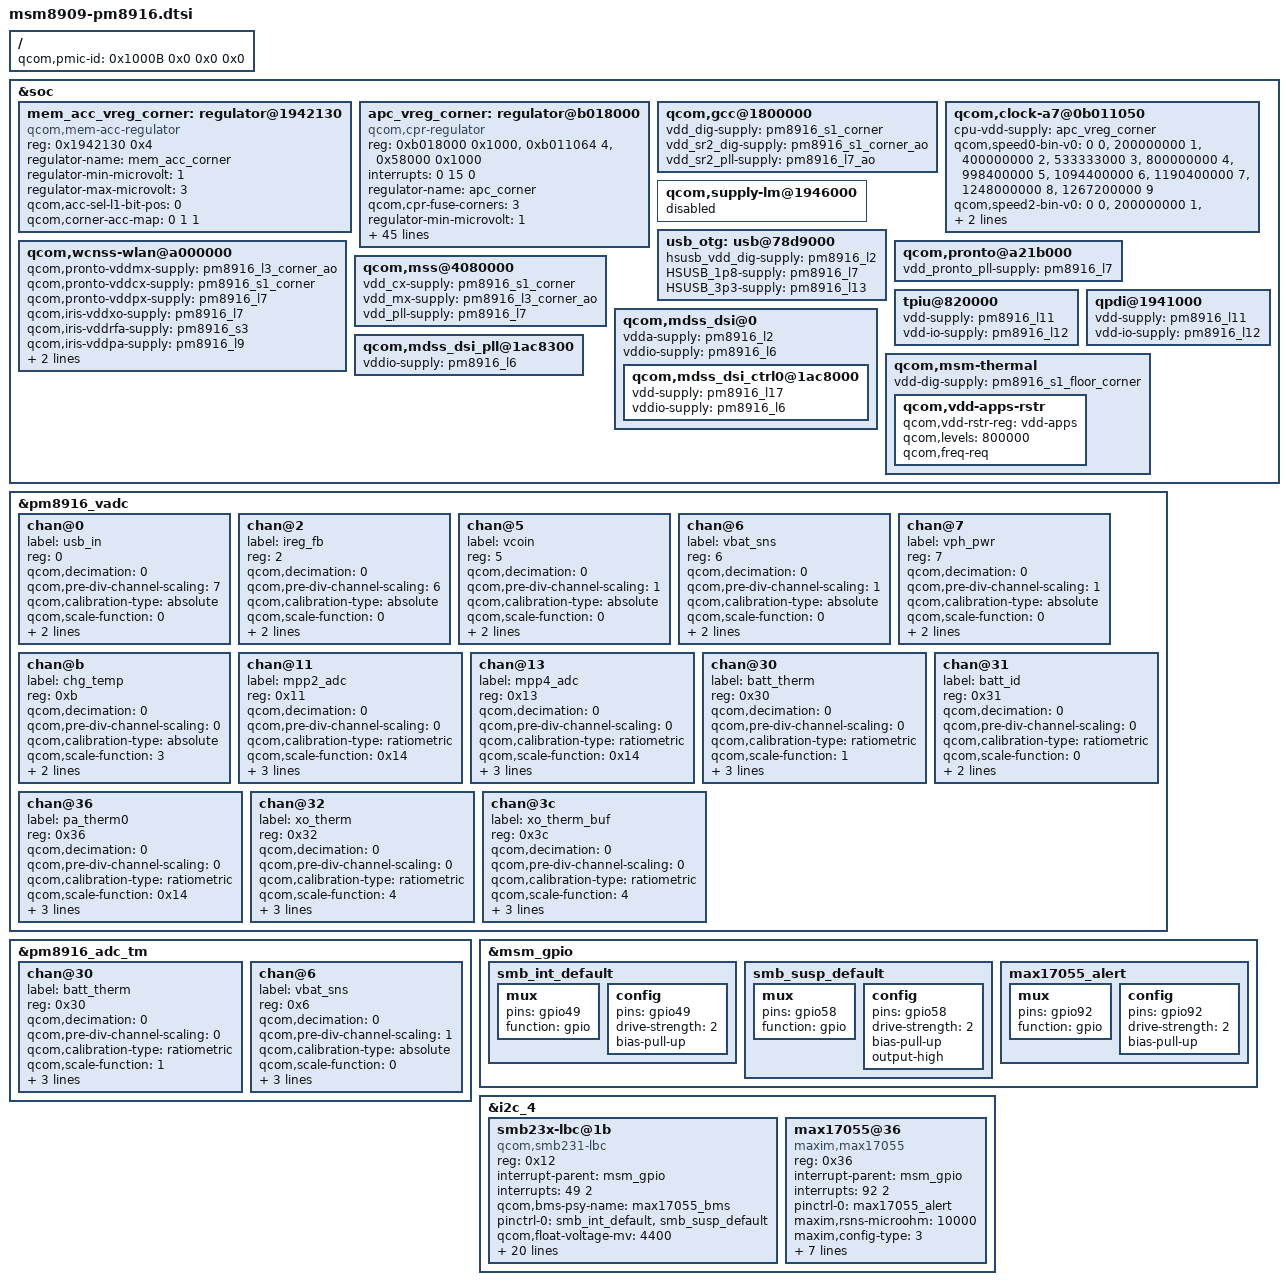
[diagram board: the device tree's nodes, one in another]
/*
 * Copyright (c) 2014-2016, The Linux Foundation. All rights reserved.
 *
 * This program is free software; you can redistribute it and/or modify
 * it under the terms of the GNU General Public License version 2 and
 * only version 2 as published by the Free Software Foundation.
 *
 * This program is distributed in the hope that it will be useful,
 * but WITHOUT ANY WARRANTY; without even the implied warranty of
 * MERCHANTABILITY or FITNESS FOR A PARTICULAR PURPOSE.  See the
 * GNU General Public License for more details.
 */

#include "msm-pm8916-rpm-regulator.dtsi"
#include "msm-pm8916.dtsi"
#include "msm8916-regulator.dtsi"
#include "msm8909-pm8916-camera.dtsi"

/ {
	qcom,pmic-id = <0x1000B 0x0 0x0 0x0>;
};

&soc {
	/* remove msm8916 acc/cpr regulator node */
	/delete-node/ regulator@1946000;
	/delete-node/ regulator@b018000;

	mem_acc_vreg_corner: regulator@1942130 {
		compatible = "qcom,mem-acc-regulator";
		reg = <0x1942130 0x4>;
		reg-names = "acc-sel-l1";
		regulator-name = "mem_acc_corner";
		regulator-min-microvolt = <1>;
		regulator-max-microvolt = <3>;

		qcom,acc-sel-l1-bit-pos = <0>;
		qcom,corner-acc-map = <0 1 1>;
	};

	apc_vreg_corner: regulator@b018000 {
		compatible = "qcom,cpr-regulator";
		reg = <0xb018000 0x1000>, <0xb011064 4>, <0x58000 0x1000>;
		reg-names = "rbcpr", "rbcpr_clk", "efuse_addr";
		interrupts = <0 15 0>;
		regulator-name = "apc_corner";
		qcom,cpr-fuse-corners = <3>;
		regulator-min-microvolt = <1>;
		regulator-max-microvolt = <9>;

		qcom,cpr-voltage-ceiling = <1050000 1225000 1350000>;
		qcom,cpr-voltage-floor = <1050000 1050000 1155000>;
		vdd-apc-supply = <&pm8916_s2>;

		qcom,vdd-mx-corner-map = <4 5 7>;
		qcom,vdd-mx-vmin-method = <4>;
		vdd-mx-supply = <&pm8916_l3_corner_ao>;
		qcom,vdd-mx-vmax = <7>;

		mem-acc-supply = <&mem_acc_vreg_corner>;

		qcom,cpr-ref-clk = <19200>;
		qcom,cpr-timer-delay = <5000>;
		qcom,cpr-timer-cons-up = <0>;
		qcom,cpr-timer-cons-down = <2>;
		qcom,cpr-irq-line = <0>;
		qcom,cpr-step-quotient = <26>;
		qcom,cpr-up-threshold = <0>;
		qcom,cpr-down-threshold = <2>;
		qcom,cpr-idle-clocks = <15>;
		qcom,cpr-gcnt-time = <1>;
		qcom,vdd-apc-step-up-limit = <1>;
		qcom,vdd-apc-step-down-limit = <1>;
		qcom,cpr-apc-volt-step = <12500>;

		qcom,cpr-fuse-row = <26 0>;
		qcom,cpr-fuse-target-quot = <42 24 6>;
		qcom,cpr-fuse-ro-sel = <61 61 54>;
		qcom,cpr-fuse-bp-cpr-disable = <58>;
		qcom,cpr-fuse-init-voltage =
					<26 36 6 0>,
					<26 18 6 0>,
					<26 0 6 0>;
		qcom,cpr-fuse-revision = <26 59 2 0>;
		qcom,cpr-init-voltage-ref = <1050000 1225000 1350000>;
		qcom,cpr-init-voltage-step = <10000>;
		qcom,cpr-corner-map = <1 1 2 2 3 3 3 3 3>;
		qcom,cpr-init-voltage-as-ceiling;
		qcom,cpr-corner-frequency-map =
					<1 200000000>,
					<2 400000000>,
					<3 533330000>,
					<4 800000000>,
					<5 998400000>,
					<6 1094400000>,
					<7 1190400000>,
					<8 1248000000>,
					<9 1267200000>;
		qcom,speed-bin-fuse-sel = <1 34 3 0>;
		qcom,cpr-speed-bin-max-corners =
					<0 0 2 4 9>,
					<2 0 2 4 6>;
		qcom,cpr-quot-adjust-scaling-factor-max = <1400>;
		qcom,cpr-enable;
	};

	qcom,gcc@1800000 {
		vdd_dig-supply = <&pm8916_s1_corner>;
		vdd_sr2_dig-supply = <&pm8916_s1_corner_ao>;
		vdd_sr2_pll-supply = <&pm8916_l7_ao>;
	};

	qcom,clock-a7@0b011050 {
		cpu-vdd-supply = <&apc_vreg_corner>;
		qcom,speed0-bin-v0 =
			<          0 0>,
			<  200000000 1>,
			<  400000000 2>,
			<  533333000 3>,
			<  800000000 4>,
			<  998400000 5>,
			< 1094400000 6>,
			< 1190400000 7>,
			< 1248000000 8>,
			< 1267200000 9>;

		qcom,speed2-bin-v0 =
			<          0 0>,
			<  200000000 1>,
			<  400000000 2>,
			<  533333000 3>,
			<  800000000 4>,
			<  998400000 5>,
			< 1094400000 6>;
	};

	qcom,supply-lm@1946000 {
		status = "disabled";
	};

	qcom,wcnss-wlan@a000000 {
		qcom,pronto-vddmx-supply = <&pm8916_l3_corner_ao>;
		qcom,pronto-vddcx-supply = <&pm8916_s1_corner>;
		qcom,pronto-vddpx-supply = <&pm8916_l7>;
		qcom,iris-vddxo-supply   = <&pm8916_l7>;
		qcom,iris-vddrfa-supply  = <&pm8916_s3>;
		qcom,iris-vddpa-supply   = <&pm8916_l9>;
		qcom,iris-vdddig-supply  = <&pm8916_l5>;
		qcom,wcnss-adc_tm = <&pm8916_adc_tm>;
	};

	usb_otg: usb@78d9000 {
		hsusb_vdd_dig-supply = <&pm8916_l2>;
		HSUSB_1p8-supply = <&pm8916_l7>;
		HSUSB_3p3-supply = <&pm8916_l13>;
	};

	qcom,pronto@a21b000 {
		vdd_pronto_pll-supply = <&pm8916_l7>;
	};

	qcom,mss@4080000 {
		vdd_cx-supply = <&pm8916_s1_corner>;
		vdd_mx-supply = <&pm8916_l3_corner_ao>;
		vdd_pll-supply = <&pm8916_l7>;
	};

	tpiu@820000 {
		vdd-supply = <&pm8916_l11>;
		vdd-io-supply = <&pm8916_l12>;
	};

	qpdi@1941000 {
		vdd-supply = <&pm8916_l11>;
		vdd-io-supply = <&pm8916_l12>;
	};

	qcom,mdss_dsi@0 {
		vdda-supply = <&pm8916_l2>;
		vddio-supply = <&pm8916_l6>;

		qcom,mdss_dsi_ctrl0@1ac8000 {
			vdd-supply = <&pm8916_l17>;
			vddio-supply = <&pm8916_l6>;
		};
	};

	qcom,mdss_dsi_pll@1ac8300 {
		vddio-supply = <&pm8916_l6>;
	};

	qcom,msm-thermal {
		vdd-dig-supply = <&pm8916_s1_floor_corner>;

		qcom,vdd-apps-rstr {
			qcom,vdd-rstr-reg = "vdd-apps";
			qcom,levels = <800000>;
			qcom,freq-req;
		};
	};
};


&pm8916_vadc {
	chan@0 {
		label = "usb_in";
		reg = <0>;
		qcom,decimation = <0>;
		qcom,pre-div-channel-scaling = <7>;
		qcom,calibration-type = "absolute";
		qcom,scale-function = <0>;
		qcom,hw-settle-time = <0>;
		qcom,fast-avg-setup = <0>;
	};

	chan@2 {
		label = "ireg_fb";
		reg = <2>;
		qcom,decimation = <0>;
		qcom,pre-div-channel-scaling = <6>;
		qcom,calibration-type = "absolute";
		qcom,scale-function = <0>;
		qcom,hw-settle-time = <0>;
		qcom,fast-avg-setup = <0>;
	};

	chan@5 {
		label = "vcoin";
		reg = <5>;
		qcom,decimation = <0>;
		qcom,pre-div-channel-scaling = <1>;
		qcom,calibration-type = "absolute";
		qcom,scale-function = <0>;
		qcom,hw-settle-time = <0>;
		qcom,fast-avg-setup = <0>;
	};

	chan@6 {
		label = "vbat_sns";
		reg = <6>;
		qcom,decimation = <0>;
		qcom,pre-div-channel-scaling = <1>;
		qcom,calibration-type = "absolute";
		qcom,scale-function = <0>;
		qcom,hw-settle-time = <0>;
		qcom,fast-avg-setup = <0>;
	};

	chan@7 {
		label = "vph_pwr";
		reg = <7>;
		qcom,decimation = <0>;
		qcom,pre-div-channel-scaling = <1>;
		qcom,calibration-type = "absolute";
		qcom,scale-function = <0>;
		qcom,hw-settle-time = <0>;
		qcom,fast-avg-setup = <0>;
	};

	chan@b {
		label = "chg_temp";
		reg = <0xb>;
		qcom,decimation = <0>;
		qcom,pre-div-channel-scaling = <0>;
		qcom,calibration-type = "absolute";
		qcom,scale-function = <3>;
		qcom,hw-settle-time = <0>;
		qcom,fast-avg-setup = <0>;
	};
	chan@11 {
		label = "mpp2_adc";
		reg = <0x11>;
		qcom,decimation = <0>;
		qcom,pre-div-channel-scaling = <0>;
		qcom,calibration-type = "ratiometric";
		qcom,scale-function = <0x14>;
		qcom,hw-settle-time = <2>;
		qcom,fast-avg-setup = <0>;
		qcom,vadc-thermal-node;
	};
	chan@13 {
		label = "mpp4_adc";
		reg = <0x13>;
		qcom,decimation = <0>;
		qcom,pre-div-channel-scaling = <0>;
		qcom,calibration-type = "ratiometric";
		qcom,scale-function = <0x14>;
		qcom,hw-settle-time = <2>;
		qcom,fast-avg-setup = <0>;
		qcom,vadc-thermal-node;
	};
	chan@30 {
		label = "batt_therm";
		reg = <0x30>;
		qcom,decimation = <0>;
		qcom,pre-div-channel-scaling = <0>;
		qcom,calibration-type = "ratiometric";
		qcom,scale-function = <1>;
		qcom,hw-settle-time = <0xb>;
		qcom,fast-avg-setup = <0>;
		qcom,vadc-thermal-node;
	};

	chan@31 {
		label = "batt_id";
		reg = <0x31>;
		qcom,decimation = <0>;
		qcom,pre-div-channel-scaling = <0>;
		qcom,calibration-type = "ratiometric";
		qcom,scale-function = <0>;
		qcom,hw-settle-time = <0xb>;
		qcom,fast-avg-setup = <0>;
	};

	chan@36 {
		label = "pa_therm0";
		reg = <0x36>;
		qcom,decimation = <0>;
		qcom,pre-div-channel-scaling = <0>;
		qcom,calibration-type = "ratiometric";
		qcom,scale-function = <0x14>;
		qcom,hw-settle-time = <2>;
		qcom,fast-avg-setup = <0>;
		qcom,vadc-thermal-node;
	};

	chan@32 {
		label = "xo_therm";
		reg = <0x32>;
		qcom,decimation = <0>;
		qcom,pre-div-channel-scaling = <0>;
		qcom,calibration-type = "ratiometric";
		qcom,scale-function = <4>;
		qcom,hw-settle-time = <2>;
		qcom,fast-avg-setup = <0>;
		qcom,vadc-thermal-node;
	};

	chan@3c {
		label = "xo_therm_buf";
		reg = <0x3c>;
		qcom,decimation = <0>;
		qcom,pre-div-channel-scaling = <0>;
		qcom,calibration-type = "ratiometric";
		qcom,scale-function = <4>;
		qcom,hw-settle-time = <2>;
		qcom,fast-avg-setup = <0>;
		qcom,vadc-thermal-node;
	};
};

&pm8916_adc_tm {
	/* Channel Node */
	chan@30 {
		label = "batt_therm";
		reg = <0x30>;
		qcom,decimation = <0>;
		qcom,pre-div-channel-scaling = <0>;
		qcom,calibration-type = "ratiometric";
		qcom,scale-function = <1>;
		qcom,hw-settle-time = <0xb>;
		qcom,fast-avg-setup = <0x2>;
		qcom,btm-channel-number = <0x48>;
	};

	chan@6 {
		label = "vbat_sns";
		reg = <0x6>;
		qcom,decimation = <0>;
		qcom,pre-div-channel-scaling = <1>;
		qcom,calibration-type = "absolute";
		qcom,scale-function = <0>;
		qcom,hw-settle-time = <0xb>;
		qcom,fast-avg-setup = <0x2>;
		qcom,btm-channel-number = <0x68>;
	};
};
&msm_gpio {
	/* Delete gpio58 configuration */
	/delete-node/ tpiu_seta_14;
	/delete-node/ smb_int_pin;
	smb_int_default: smb_int_default {
		mux {
			pins = "gpio49";
			function = "gpio";
		};
		config {
			pins = "gpio49";
			drive-strength = <2>;   /* 2 MA */
			bias-pull-up;           /* PULL UP*/
		};
	};

	smb_susp_default: smb_susp_default {
		mux {
			pins = "gpio58";
			function ="gpio";
		};
		config {
			pins = "gpio58";
			drive-strength = <2>;   /* 2 MA */
			bias-pull-up;           /* PULL UP*/
			output-high;
		};
	};

	max17055_alert: max17055_alert {
		mux {
			pins = "gpio92";
			function = "gpio";
		};
		config {
			pins = "gpio92";
			drive-strength = <2>;   /* 2 MA */
			bias-pull-up;           /* PULL UP*/
		};
	};
};
&i2c_4 {
	smb23x-lbc@1b {
		compatible = "qcom,smb231-lbc";
		reg = <0x12>;
		interrupt-parent = <&msm_gpio>;
		interrupts = <49 2>;
		qcom,bms-psy-name = "max17055_bms";
		pinctrl-names = "default";
		pinctrl-0 = <&smb_int_default &smb_susp_default>;
		qcom,float-voltage-mv = <4400>;
		qcom,charging-timeout = <360>;
		qcom,recharge-thresh-mv = <80>;
		qcom,iterm-ma = <20>;
		qcom,fastchg-ma = <500>;
		qcom,hot-bat-decidegc = <500>;
		qcom,warm-bat-decidegc = <450>;
		qcom,cool-bat-decidegc = <100>;
		qcom,cold-bat-decidegc = <0>;
		zte,batt-cold-percentage = <80>;
		zte,batt-hot-percentage = <25>;
		zte,soft-warm-current-comp-ma = <250>;
		zte,soft-cool-current-comp-ma = <100>;
		zte,soft-warm-vfloat-comp-mv = <4150>;
		zte,soft-cool-vfloat-comp-mv = <4250>;
		qcom,soft-temp-vfloat-comp-mv = <200>;
		qcom,soft-temp-current-comp-ma = <150>;
		qcom,chg-inhibit-disabled;
		qcom,apsd-disabled;
		qcom,thermal-mitigation = <1500 900 500 100>;
		qcom,smb23x-vadc = <&pm8916_vadc>;
	};
	max17055@36 {
		status = "okay";
		compatible = "maxim,max17055";
		reg = <0x36>;

		interrupt-parent = <&msm_gpio>;
		interrupts = <92 2>;			/* gpio92 */
		pinctrl-names = "default";
		pinctrl-0 = <&max17055_alert>;

		maxim,rsns-microohm = <10000>;	/*Current sense resistance in micro Ohm*/
		maxim,config-type = <3>;		/*EZ:1 SHORT: 2 FULL: 3*/
		maxim,cold-temp = <(-450)>;		/*Temp is scaled by 10 to reserve more precise*/
		maxim,over-heat-temp = <1000>;	/*Temp is scaled by 10 to reserve more precise*/
		maxim,dead-volt = <2800>;		/*Dead voltage in millivolts*/
		maxim,over-volt = <4500>;		/*Over voltage in millivolts*/
		maxim,enable-por-init;			/*Comment out this line to ignore the configuration data*/
		maxim,config-data = /bits/ 16 <
			0x0000 0x0000 0x0000 0x0000 0x0000		/* A/D measurement */
			0x0000 0x0000 0x0000 0x0000 0x0000 0x00d8 0xe000	/* Alert / Status */
			0x0000 0x0000 0x040c 0x00c0 0x0000 0xaa64 0x8400	/* App data */
			0x0000 0x4412 0x0000 0x0000 0x0000 0x860b		/* Configs */
			0x0049 0x343f 0x5400 0x2483 0x0c86 0x0a07		/* Cell Data */
			0x7d00 0xaad0 0xb7b0 0xb9a0 0xbc50 0xbda0 0xbe80 0xbfb0		/* Model Data Begin*/
			0xc210 0xc360 0xc690 0xc9b0 0xcc50 0xceb0 0xd530 0xdb40
			0x0020 0x0180 0x1730 0x0d00 0x19e0 0x13c0 0x12f0 0x0f80
			0x0a50 0x08f0 0x06f0 0x07f0 0x0890 0x06e0 0x05f0 0x05f0
			0x0100 0x0100 0x0100 0x0100 0x0100 0x0100 0x0100 0x0100
			0x0100 0x0100 0x0100 0x0100 0x0100 0x0100 0x0100 0x0100		/* Model Data End*/
		>;
	};
};

#include "msm8909-pm8916-pm.dtsi"
